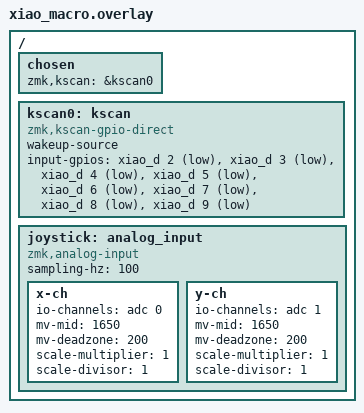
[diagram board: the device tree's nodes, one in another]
#include <dt-bindings/zmk/matrix_transform.h>
#include <dt-bindings/zmk/input_transform.h>

/ {
    chosen {
        zmk,kscan = &kscan0;
    };

    kscan0: kscan {
        compatible = "zmk,kscan-gpio-direct";
        wakeup-source;

        input-gpios =
            <&xiao_d 2 (GPIO_ACTIVE_LOW | GPIO_PULL_UP)>,
            <&xiao_d 3 (GPIO_ACTIVE_LOW | GPIO_PULL_UP)>,
            <&xiao_d 4 (GPIO_ACTIVE_LOW | GPIO_PULL_UP)>,
            <&xiao_d 5 (GPIO_ACTIVE_LOW | GPIO_PULL_UP)>,
            <&xiao_d 6 (GPIO_ACTIVE_LOW | GPIO_PULL_UP)>,
            <&xiao_d 7 (GPIO_ACTIVE_LOW | GPIO_PULL_UP)>,
            <&xiao_d 8 (GPIO_ACTIVE_LOW | GPIO_PULL_UP)>,
            <&xiao_d 9 (GPIO_ACTIVE_LOW | GPIO_PULL_UP)>;
    };
    // アナログスティックの設定 (A0: X軸, A1: Y軸)
    joystick: analog_input {
        compatible = "zmk,analog-input";
        sampling-hz = <100>;
        x-ch {
            io-channels = <&adc 0>; // A0ピン
            mv-mid = <1650>;        // 中央値(mV)
            mv-deadzone = <200>;     // デッドゾーン(mV)
            scale-multiplier = <1>;
            scale-divisor = <1>;
        };
        y-ch {
            io-channels = <&adc 1>; // A1ピン
            mv-mid = <1650>;        // 中央値(mV)
            mv-deadzone = <200>;     // デッドゾーン(mV)
            scale-multiplier = <1>;
            scale-divisor = <1>;
        };
     };
};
